# STM32H7B3x register map
File version: 2.2
CPU: CM7 r0p1, little endian, MPU, FPU, 4 interrupt priority bits
Registers are 32-bit, read-write, reset 0x0 unless marked. A register's access mark holds for its fields unless they carry their own. Offsets are from the block's base; [hi:lo] are bit positions; lines under a group give offsets from that group; {n}, {i} and the like mark numbered series; 'fields as' and 'values as' point back to an identical list.

## OTFDEC1 — On-The-Fly Decryption engine
Base 0x5200B800
Same registers: OTFDEC2 0x5200BC00
0x00 CR — OTFDEC control register
  [0] ENC — Encryption mode bit
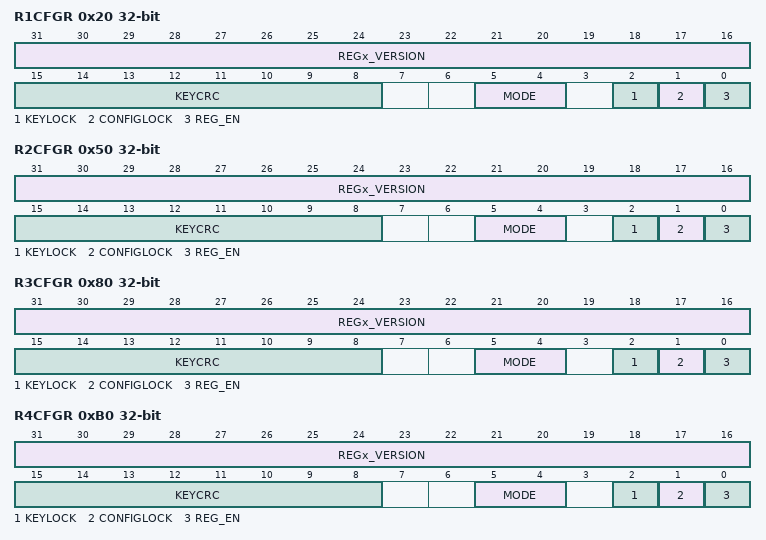
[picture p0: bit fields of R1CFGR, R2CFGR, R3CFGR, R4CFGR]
0x20 R1CFGR access per field — OTFDEC region x configuration register
  [31:16] REGx_VERSION rw — region firmware version
  [15:8] KEYCRC ro — region key 8-bit CRC
  [5:4] MODE rw — operating mode
  [2] KEYLOCK rw — region key lock
  [1] CONFIGLOCK rw — region config lock
  [0] REG_EN rw — region on-the-fly decryption enable
0x24 R1STARTADDR — OTFDEC region x start address register
  [31:0] REGx_START_ADDR — Region AXI start address
0x28 R1ENDADDR reset 0xFFF — OTFDEC region x end address register
  [31:0] REGx_END_ADDR — Region AXI end address
0x2C R1NONCER0 — OTFDEC region x nonce register 0
  [31:0] REGx_NONCE
0x30 R1NONCER1 — OTFDEC region x nonce register 1
  [31:0] REGx_NONCE — Region nonce
{0x4+0x30*i} R{i}KEYR0 wo (i=1..4) — OTFDEC region x key register 0
  [31:0] REGx_KEY
{0x8+0x30*i} R{i}KEYR1 wo (i=1..4) — OTFDEC region x key register 1
  [31:0] REGx_KEY
0x3C R1KEYR2 wo — OTFDEC region x key register 2
  [31:0] REGx_KEY
{0x10+0x30*i} R{i}KEYR3 wo (i=1..4) — OTFDEC region x key register 3
  [31:0] REGx_KEY
0x50 R2CFGR access per field — OTFDEC region x configuration register
  fields as R1CFGR
0x54 R2STARTADDR — OTFDEC region x start address register
  [31:0] REGx_START_ADDR — Region AXI start address
0x58 R2ENDADDR reset 0xFFF — OTFDEC region x end address register
  [31:0] REGx_END_ADDR — Region AXI end address
0x5C R2NONCER0 — OTFDEC region x nonce register 0
  [31:0] REGx_NONCE
0x60 R2NONCER1 — OTFDEC region x nonce register 1
  [31:0] REGx_NONCE — Region nonce, bits [63:32]REGx_NONCE[63:32]
0x6C R2KEYR2 wo — OTFDEC region x key register 2
  [31:0] REGx_KEY_
0x80 R3CFGR access per field — OTFDEC region x configuration register
  fields as R1CFGR
0x84 R3STARTADDR — OTFDEC region x start address register
  [31:0] REGx_START_ADDR — Region AXI start address
0x88 R3ENDADDR reset 0xFFF — OTFDEC region x end address register
  [31:0] REGx_END_ADDR — Region AXI end address
0x8C R4ENDADDR reset 0xFFF — OTFDEC region x end address register
  [31:0] REGx_END_ADDR — Region AXI end address
0x8C R3NONCER0 (alternate view of R4ENDADDR) — OTFDEC region x nonce register 0
  [31:0] REGx_NONCE
0x90 R3NONCER1 — OTFDEC region x nonce register 1
  [31:0] REGx_NONCE
0x9C R3KEYR2 wo — OTFDEC region x key register 2
  [31:0] REGx_KEY
0xB0 R4CFGR access per field — OTFDEC region x configuration register
  fields as R1CFGR
0xB4 R4STARTADDR — OTFDEC region x start address register
  [31:0] REGx_START_ADDR — Region AXI start address
0xBC R4NONCER0 — OTFDEC region x nonce register 0
  [31:0] REGx_NONCE
0xC0 R4NONCER1 — OTFDEC region x nonce register 1
  [31:0] REGx_NONCE
0xCC R4KEYR2 wo — OTFDEC region x key register 2
  [31:0] REGx_KEY
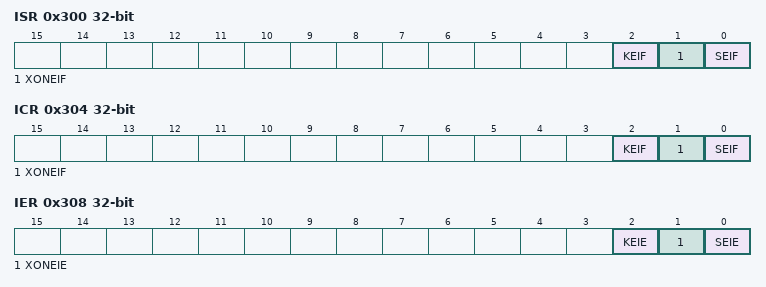
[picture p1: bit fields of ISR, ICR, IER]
0x300 ISR ro — OTFDEC interrupt status register
  [2] KEIF — Key Error Interrupt Flag status
  [1] XONEIF — Execute-only execute-Never Error Interrupt Flag status
  [0] SEIF — Security Error Interrupt Flag status
0x304 ICR ro — OTFDEC interrupt clear register
  [2] KEIF
  [1] XONEIF — Execute-only execute-Never Error Interrupt Flag clear
  [0] SEIF
0x308 IER — OTFDEC interrupt enable register
  [2] KEIE
  [1] XONEIE
  [0] SEIE — Security Error Interrupt Enable

## OTG1_HS_HOST — USB 1 on the go high speed
Base 0x40040400
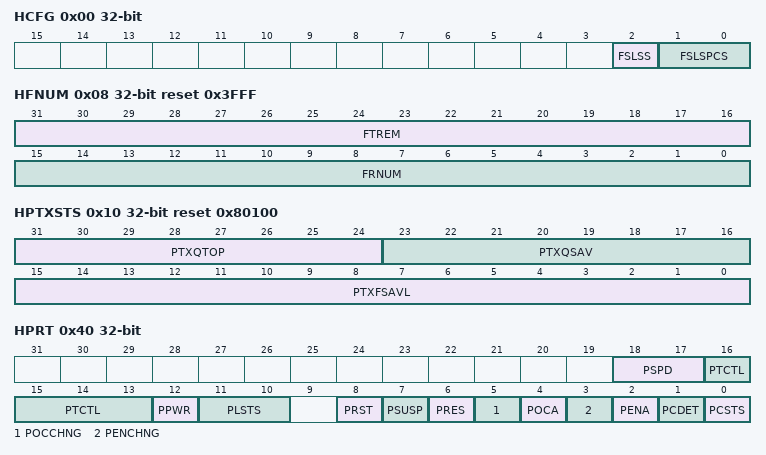
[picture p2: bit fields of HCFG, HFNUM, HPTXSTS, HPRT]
0x00 HCFG access per field — OTG_HS host configuration register
  [2] FSLSS ro — FS- and LS-only support
  [1:0] FSLSPCS rw — FS/LS PHY clock select
0x04 HFIR reset 0xEA60 — OTG_HS Host frame interval register
  [15:0] FRIVL — Frame interval
0x08 HFNUM ro reset 0x3FFF — OTG_HS host frame number/frame time remaining register
  [31:16] FTREM — Frame time remaining
  [15:0] FRNUM — Frame number
0x10 HPTXSTS access per field reset 0x80100 — OTG_HS_Host periodic transmit FIFO/queue status register
  [31:24] PTXQTOP ro — Top of the periodic transmit request queue
  [23:16] PTXQSAV ro — Periodic transmit request queue space available
  [15:0] PTXFSAVL rw — Periodic transmit data FIFO space available
0x14 HAINT ro — OTG_HS Host all channels interrupt register
  [15:0] HAINT — Channel interrupts
0x18 HAINTMSK — OTG_HS host all channels interrupt mask register
  [15:0] HAINTM — Channel interrupt mask
0x40 HPRT access per field — OTG_HS host port control and status register
  [18:17] PSPD ro — Port speed
  [16:13] PTCTL rw — Port test control
  [12] PPWR rw — Port power
  [11:10] PLSTS ro — Port line status
  [8] PRST rw — Port reset
  [7] PSUSP rw — Port suspend
  [6] PRES rw — Port resume
  [5] POCCHNG rw — Port overcurrent change
  [4] POCA ro — Port overcurrent active
  [3] PENCHNG rw — Port enable/disable change
  [2] PENA rw — Port enable
  [1] PCDET rw — Port connect detected
  [0] PCSTS ro — Port connect status
{0x100+0x20*i} HC{i} (i=0..15) group — Host channel
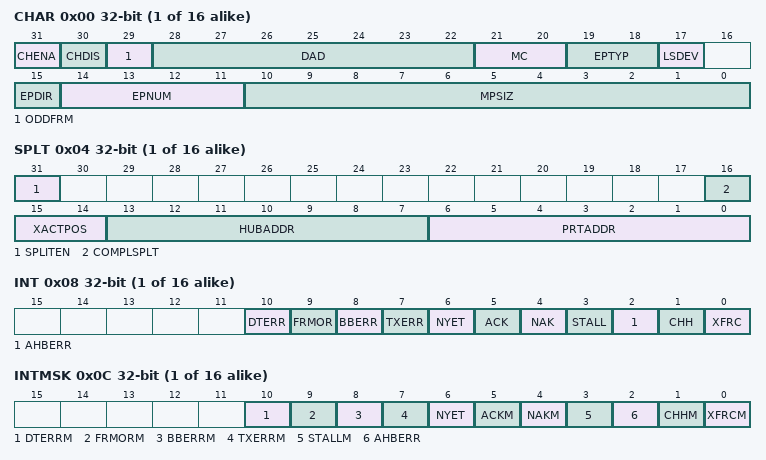
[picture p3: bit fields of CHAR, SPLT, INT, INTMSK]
  0x00 CHAR — OTG_HS host channel-0 characteristics register
    [31] CHENA — Channel enable
    [30] CHDIS — Channel disable
    [29] ODDFRM — Odd frame
    [28:22] DAD — Device address
    [21:20] MC — Multi Count (MC) / Error Count (EC)
    [19:18] EPTYP — Endpoint type
    [17] LSDEV — Low-speed device
    [15] EPDIR — Endpoint direction
    [14:11] EPNUM — Endpoint number
    [10:0] MPSIZ — Maximum packet size
  0x04 SPLT — OTG_HS host channel-0 split control register
    [31] SPLITEN — Split enable
    [16] COMPLSPLT — Do complete split
    [15:14] XACTPOS
    [13:7] HUBADDR — Hub address
    [6:0] PRTADDR — Port address
  0x08 INT — OTG_HS host channel-11 interrupt register
    [10] DTERR — Data toggle error
    [9] FRMOR — Frame overrun
    [8] BBERR — Babble error
    [7] TXERR — Transaction error
    [6] NYET — Response received interrupt
    [5] ACK — ACK response received/transmitted interrupt
    [4] NAK — NAK response received interrupt
    [3] STALL — STALL response received interrupt
    [2] AHBERR — AHB error
    [1] CHH — Channel halted
    [0] XFRC — Transfer completed
  0x0C INTMSK — OTG_HS host channel-11 interrupt mask register
    [10] DTERRM — Data toggle error mask
    [9] FRMORM — Frame overrun mask
    [8] BBERRM — Babble error mask
    [7] TXERRM — Transaction error mask
    [6] NYET — response received interrupt mask
    [5] ACKM — ACK response received/transmitted interrupt mask
    [4] NAKM — NAK response received interrupt mask
    [3] STALLM — STALL response received interrupt mask
    [2] AHBERR — AHB error
    [1] CHHM — Channel halted mask
    [0] XFRCM — Transfer completed mask
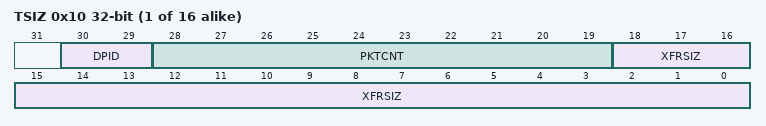
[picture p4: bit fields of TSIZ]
  0x10 TSIZ — OTG_HS host channel-11 transfer size register
    [30:29] DPID — Data PID
    [28:19] PKTCNT — Packet count
    [18:0] XFRSIZ — Transfer size
  0x14 DMA — OTG_HS host channel-0 DMA address register
    [31:0] DMAADDR — DMA address
